# CY8C5888LTI_LP097 register map
File version: 0.1
CY8C58LP
Registers are 8-bit, read-write, no defined reset value unless marked. A register's access mark holds for its fields unless they carry their own. Offsets are from the block's base; lines under a group give offsets from that group; [hi:lo] are bit positions; {n}, {i} and the like mark numbered series; 'fields as' and 'values as' point back to an identical list; <NAME> marks a mode.

## Memory map
0x00000000 MIDI2_UART — UART
0x00000000 MIDI1_UART — UART
0x00000000 USB — USBFS
0x00000000 SleepTimer
0x40006470 Keys_Notes_4
0x40006473 Keys_Notes_3
0x40006475 Keys_Notes_1
0x40006476 Keys_Notes_2
0x40006478 Bass_Notes
0x4000647A Chorus_Speed
0x4000647B Chords_Bass_Notes
0x4000647C Chords_Notes
0x4000647D Keys_Notes_6
0x4000647F Keys_Notes_5
0x40006574 Control_Reg_10
0x40006575 Control_Reg_11
0x40006576 Tabs_2
0x40006577 Tabs_4
0x40006578 Tabs_1
0x4000657B Tabs_3

## Keys_Notes_2
Base 0x40006476
0x00 Keys_Notes_2_CONTROL_REG

## Keys_Notes_1
Base 0x40006475
Registers as Keys_Notes_2 (with Keys_Notes_2 read as Keys_Notes_1).

## Keys_Notes_3
Base 0x40006473
Registers as Keys_Notes_2 (with Keys_Notes_2 read as Keys_Notes_3).

## Keys_Notes_4
Base 0x40006470
Registers as Keys_Notes_2 (with Keys_Notes_2 read as Keys_Notes_4).

## Tabs_4
Base 0x40006577
Registers as Keys_Notes_2 (with Keys_Notes_2 read as Tabs_4).

## Tabs_3
Base 0x4000657B
Registers as Keys_Notes_2 (with Keys_Notes_2 read as Tabs_3).

## Chords_Notes
Base 0x4000647C
Registers as Keys_Notes_2 (with Keys_Notes_2 read as Chords_Notes).

## Chords_Bass_Notes
Base 0x4000647B
Registers as Keys_Notes_2 (with Keys_Notes_2 read as Chords_Bass_Notes).

## Keys_Notes_6
Base 0x4000647D
Registers as Keys_Notes_2 (with Keys_Notes_2 read as Keys_Notes_6).

## Keys_Notes_5
Base 0x4000647F
Registers as Keys_Notes_2 (with Keys_Notes_2 read as Keys_Notes_5).

## Bass_Notes
Base 0x40006478
Registers as Keys_Notes_2 (with Keys_Notes_2 read as Bass_Notes).

## Tabs_1
Base 0x40006578
Registers as Keys_Notes_2 (with Keys_Notes_2 read as Tabs_1).

## Tabs_2
Base 0x40006576
Registers as Keys_Notes_2 (with Keys_Notes_2 read as Tabs_2).

## Chorus_Speed
Base 0x4000647A
Registers as Keys_Notes_2 (with Keys_Notes_2 read as Chorus_Speed).

## Control_Reg_10
Base 0x40006574
Registers as Keys_Notes_2 (with Keys_Notes_2 read as Control_Reg_10).

## Control_Reg_11
Base 0x40006575
Registers as Keys_Notes_2 (with Keys_Notes_2 read as Control_Reg_11).

## MIDI2_UART — UART
Base 0x00000000
0x40006441 TX_MIDI2_UART_TX_DATA — TX Data Register
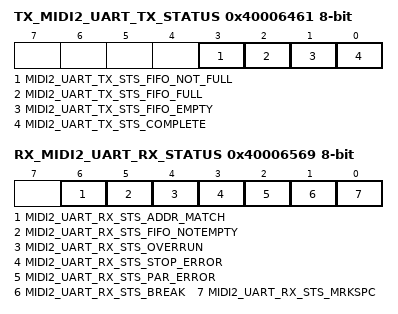
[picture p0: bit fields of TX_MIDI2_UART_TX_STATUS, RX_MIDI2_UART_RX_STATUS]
0x40006461 TX_MIDI2_UART_TX_STATUS — TX status register
  [3] MIDI2_UART_TX_STS_FIFO_NOT_FULL ro, [2] MIDI2_UART_TX_STS_FIFO_FULL ro, [1] MIDI2_UART_TX_STS_FIFO_EMPTY ro, [0] MIDI2_UART_TX_STS_COMPLETE ro
0x4000652A RX_MIDI2_UART_RX_ADDRESS1 — RX Address1 Register
0x4000653A RX_MIDI2_UART_RX_ADDRESS2 — RX Address2 Register
0x4000654A RX_MIDI2_UART_RX_DATA — RX Data Register
0x40006569 RX_MIDI2_UART_RX_STATUS — RX status register
  [6] MIDI2_UART_RX_STS_ADDR_MATCH ro, [5] MIDI2_UART_RX_STS_FIFO_NOTEMPTY ro, [4] MIDI2_UART_RX_STS_OVERRUN ro, [3] MIDI2_UART_RX_STS_STOP_ERROR ro, [2] MIDI2_UART_RX_STS_PAR_ERROR ro, [1] MIDI2_UART_RX_STS_BREAK ro, [0] MIDI2_UART_RX_STS_MRKSPC ro

## MIDI1_UART — UART
Base 0x00000000
0x40006446 TX_MIDI1_UART_TX_DATA — TX Data Register
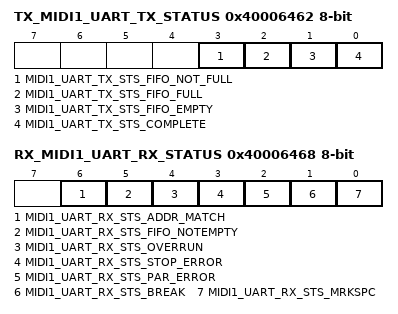
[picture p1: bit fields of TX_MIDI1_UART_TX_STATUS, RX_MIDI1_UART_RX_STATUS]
0x40006462 TX_MIDI1_UART_TX_STATUS — TX status register
  [3] MIDI1_UART_TX_STS_FIFO_NOT_FULL ro, [2] MIDI1_UART_TX_STS_FIFO_FULL ro, [1] MIDI1_UART_TX_STS_FIFO_EMPTY ro, [0] MIDI1_UART_TX_STS_COMPLETE ro
0x40006468 RX_MIDI1_UART_RX_STATUS — RX status register
  [6] MIDI1_UART_RX_STS_ADDR_MATCH ro, [5] MIDI1_UART_RX_STS_FIFO_NOTEMPTY ro, [4] MIDI1_UART_RX_STS_OVERRUN ro, [3] MIDI1_UART_RX_STS_STOP_ERROR ro, [2] MIDI1_UART_RX_STS_PAR_ERROR ro, [1] MIDI1_UART_RX_STS_BREAK ro, [0] MIDI1_UART_RX_STS_MRKSPC ro
0x40006529 RX_MIDI1_UART_RX_ADDRESS1 — RX Address1 Register
0x40006539 RX_MIDI1_UART_RX_ADDRESS2 — RX Address2 Register
0x40006549 RX_MIDI1_UART_RX_DATA — RX Data Register
